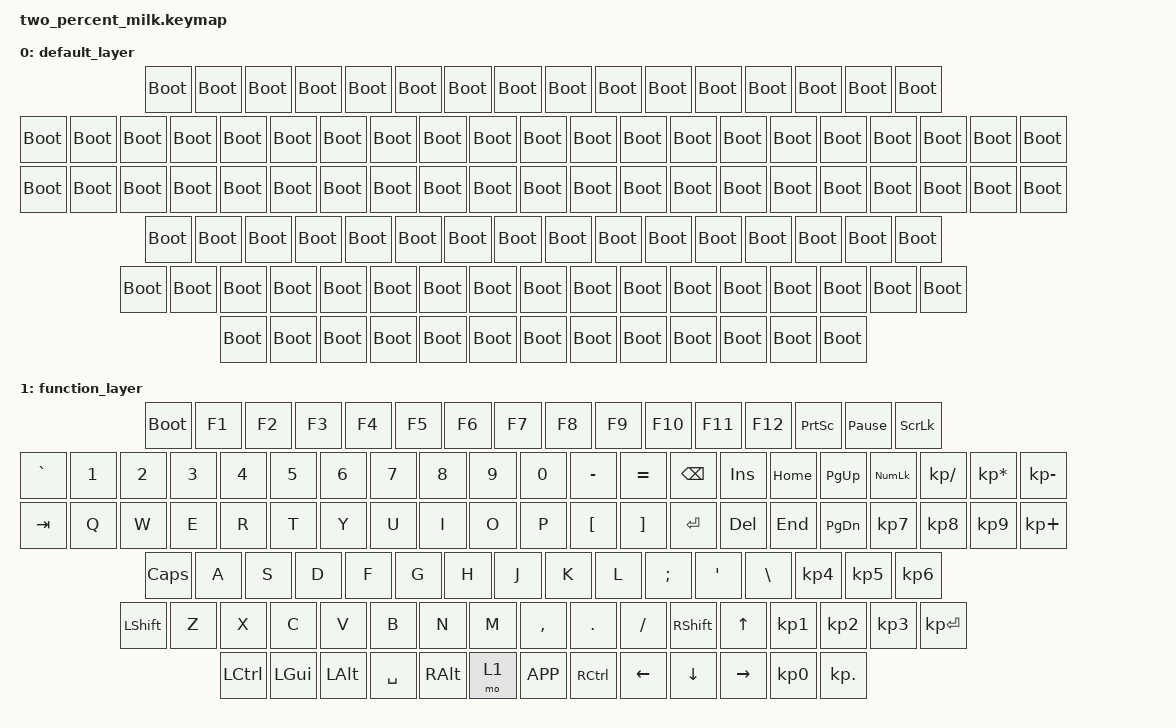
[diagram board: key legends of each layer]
/*
 * Copyright (c) 2022 The ZMK Contributors
 *
 * SPDX-License-Identifier: MIT
 */

#include <behaviors.dtsi>
#include <dt-bindings/zmk/keys.h>
#include <dt-bindings/zmk/bt.h>

/ {

    keymap {
        compatible = "zmk,keymap";

        default_layer {
            bindings = <
            &bootloader
            &bootloader
            &bootloader
            &bootloader
            &bootloader
            &bootloader
            &bootloader
            &bootloader
            &bootloader
            &bootloader
            &bootloader
            &bootloader
            &bootloader
            &bootloader
            &bootloader
            &bootloader
            &bootloader
            &bootloader
            &bootloader
            &bootloader
            &bootloader
            &bootloader
            &bootloader
            &bootloader
            &bootloader
            &bootloader
            &bootloader
            &bootloader
            &bootloader
            &bootloader
            &bootloader
            &bootloader
            &bootloader
            &bootloader
            &bootloader
            &bootloader
            &bootloader
            &bootloader
            &bootloader
            &bootloader
            &bootloader
            &bootloader
            &bootloader
            &bootloader
            &bootloader
            &bootloader
            &bootloader
            &bootloader
            &bootloader
            &bootloader
            &bootloader
            &bootloader
            &bootloader
            &bootloader
            &bootloader
            &bootloader
            &bootloader
            &bootloader
            &bootloader
            &bootloader
            &bootloader
            &bootloader
            &bootloader
            &bootloader
            &bootloader
            &bootloader
            &bootloader
            &bootloader
            &bootloader
            &bootloader
            &bootloader
            &bootloader
            &bootloader
            &bootloader
            &bootloader
            &bootloader
            &bootloader
            &bootloader
            &bootloader
            &bootloader
            &bootloader
            &bootloader
            &bootloader
            &bootloader
            &bootloader
            &bootloader
            &bootloader
            &bootloader
            &bootloader
            &bootloader
            &bootloader
            &bootloader
            &bootloader
            &bootloader
            &bootloader
            &bootloader
            &bootloader
            &bootloader
            &bootloader
            &bootloader
            &bootloader
            &bootloader
            &bootloader
            &bootloader
            >;
        };
        function_layer {
            bindings = <
                &bootloader  &kp F1 &kp F2 &kp F3 &kp F4 &kp F5 &kp F6 &kp F7 &kp F8 &kp F9 &kp F10 &kp F11 &kp F12 &kp PSCRN &kp PAUSE_BREAK &kp SLCK
                &kp GRAVE &kp N1 &kp N2 &kp N3 &kp N4 &kp N5 &kp N6 &kp N7 &kp N8 &kp N9 &kp N0 &kp MINUS &kp EQUAL &kp BSPC &kp INS &kp HOME &kp PG_UP &kp KP_NUM &kp KP_DIVIDE &kp KP_MULTIPLY &kp KP_MINUS
                &kp TAB &kp Q &kp W &kp E &kp R &kp T &kp Y &kp U &kp I &kp O &kp P &kp LBKT &kp RBKT &kp ENTER &kp DEL &kp END &kp PG_DN &kp KP_N7 &kp KP_N8 &kp KP_N9 &kp KP_PLUS
                &kp CAPS &kp A &kp S &kp D &kp F &kp G &kp H &kp J &kp K &kp L &kp SEMI &kp SQT &kp BSLH &kp KP_N4 &kp KP_N5 &kp KP_N6
                &kp LSHIFT &kp Z &kp X &kp C &kp V &kp B &kp N &kp M &kp COMMA &kp DOT &kp SLASH &kp RSHIFT &kp UP &kp KP_N1 &kp KP_N2 &kp KP_N3 &kp KP_ENTER
                &kp LCTRL &kp LGUI &kp LALT &kp SPACE &kp RALT &mo 1 &kp K_APP &kp RCTRL &kp LEFT &kp DOWN &kp RIGHT &kp KP_N0 &kp KP_DOT
            >;
        };
    };
};
